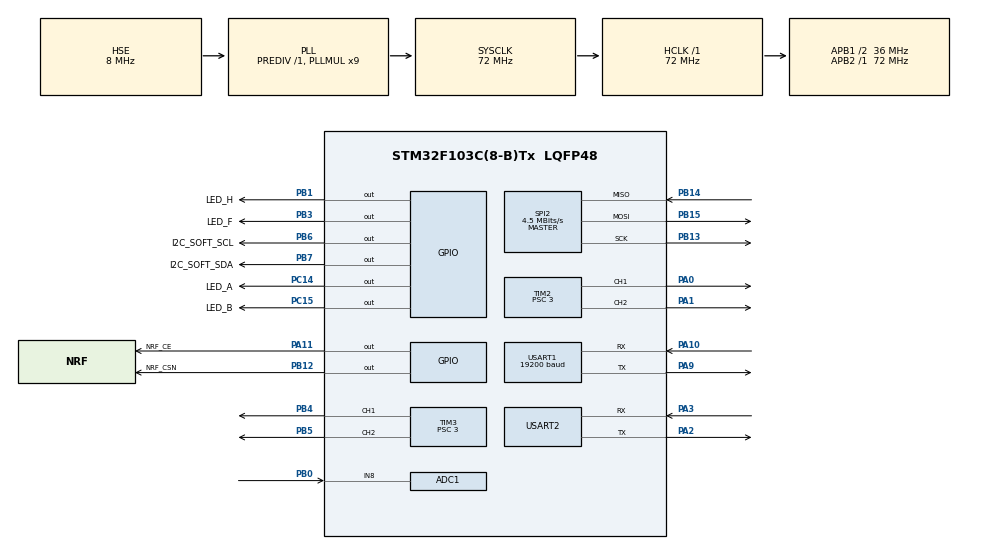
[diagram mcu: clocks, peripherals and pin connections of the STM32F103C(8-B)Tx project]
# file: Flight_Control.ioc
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ADC1.Channel-0\#ChannelRegularConversion=ADC_CHANNEL_8
ADC1.ContinuousConvMode=ENABLE
ADC1.NbrOfConversionFlag=1
ADC1.Rank-0\#ChannelRegularConversion=1
ADC1.SamplingTime-0\#ChannelRegularConversion=ADC_SAMPLETIME_55CYCLES_5
ADC1.master=1
Dma.ADC1.0.Direction=DMA_PERIPH_TO_MEMORY
Dma.ADC1.0.Instance=DMA1_Channel1
Dma.ADC1.0.MemDataAlignment=DMA_MDATAALIGN_HALFWORD
Dma.ADC1.0.MemInc=DMA_MINC_ENABLE
Dma.ADC1.0.Mode=DMA_CIRCULAR
Dma.ADC1.0.PeriphDataAlignment=DMA_PDATAALIGN_HALFWORD
Dma.ADC1.0.PeriphInc=DMA_PINC_DISABLE
Dma.ADC1.0.Priority=DMA_PRIORITY_LOW
Dma.Request0=ADC1
IWDG.Prescaler=IWDG_PRESCALER_64
IWDG.Reload=625
Mcu.Family=STM32F1
Mcu.Name=STM32F103C(8-B)Tx
Mcu.Package=LQFP48
NVIC.PriorityGroup=NVIC_PRIORITYGROUP_4
NVIC.USART1_IRQn=true\:5\:0\:true\:false\:true\:true\:true\:true
PA0-WKUP.Signal=S_TIM2_CH1_ETR
PA1.Signal=S_TIM2_CH2
PA10.Mode=Asynchronous
PA10.Signal=USART1_RX
PA11.GPIO_Label=NRF_CE
PA11.PinState=GPIO_PIN_SET
PA11.Signal=GPIO_Output
PA13.Mode=Serial_Wire
PA13.Signal=SYS_JTMS-SWDIO
PA14.Mode=Serial_Wire
PA14.Signal=SYS_JTCK-SWCLK
PA2.Mode=Asynchronous
PA2.Signal=USART2_TX
PA3.Mode=Asynchronous
PA3.Signal=USART2_RX
PA9.Mode=Asynchronous
PA9.Signal=USART1_TX
PB0.Signal=ADCx_IN8
PB1.GPIO_Label=LED_H
PB1.PinState=GPIO_PIN_SET
PB1.Signal=GPIO_Output
PB12.GPIO_Label=NRF_CSN
PB12.PinState=GPIO_PIN_SET
PB12.Signal=GPIO_Output
PB13.Mode=Full_Duplex_Master
PB13.Signal=SPI2_SCK
PB14.Mode=Full_Duplex_Master
PB14.Signal=SPI2_MISO
PB15.Mode=Full_Duplex_Master
PB15.Signal=SPI2_MOSI
PB3.GPIO_Label=LED_F
PB3.PinState=GPIO_PIN_SET
PB3.Signal=GPIO_Output
PB4.Signal=S_TIM3_CH1
PB5.Signal=S_TIM3_CH2
PB6.GPIO_Label=I2C_SOFT_SCL
PB6.GPIO_ModeDefaultOutputPP=GPIO_MODE_OUTPUT_OD
PB6.GPIO_PuPd=GPIO_NOPULL
PB6.PinState=GPIO_PIN_SET
PB6.Signal=GPIO_Output
PB7.GPIO_Label=I2C_SOFT_SDA
PB7.GPIO_ModeDefaultOutputPP=GPIO_MODE_OUTPUT_OD
PB7.GPIO_PuPd=GPIO_NOPULL
PB7.PinState=GPIO_PIN_SET
PB7.Signal=GPIO_Output
PC14-OSC32_IN.GPIO_Label=LED_A
PC14-OSC32_IN.PinState=GPIO_PIN_SET
PC14-OSC32_IN.Signal=GPIO_Output
PC15-OSC32_OUT.GPIO_Label=LED_B
PC15-OSC32_OUT.PinState=GPIO_PIN_SET
PC15-OSC32_OUT.Signal=GPIO_Output
PD0-OSC_IN.Mode=HSE-External-Oscillator
PD0-OSC_IN.Signal=RCC_OSC_IN
PD1-OSC_OUT.Mode=HSE-External-Oscillator
PD1-OSC_OUT.Signal=RCC_OSC_OUT
ProjectManager.HeapSize=0x200
ProjectManager.StackSize=0x400
ProjectManager.TargetToolchain=CMake
RCC.ADCPresc=RCC_ADCPCLK2_DIV6
RCC.AHBFreq_Value=72000000
RCC.APB1CLKDivider=RCC_HCLK_DIV2
RCC.APB1Freq_Value=36000000
RCC.APB1TimFreq_Value=72000000
RCC.APB2Freq_Value=72000000
RCC.APB2TimFreq_Value=72000000
RCC.HCLKFreq_Value=72000000
RCC.PLLMUL=RCC_PLL_MUL9
RCC.PLLSourceVirtual=RCC_PLLSOURCE_HSE
RCC.SYSCLKFreq_VALUE=72000000
RCC.SYSCLKSource=RCC_SYSCLKSOURCE_PLLCLK
RCC.USBFreq_Value=72000000
SH.ADCx_IN8.0=ADC1_IN8,IN8
SH.S_TIM2_CH1_ETR.0=TIM2_CH1,PWM Generation1 CH1
SH.S_TIM2_CH2.0=TIM2_CH2,PWM Generation2 CH2
SH.S_TIM3_CH1.0=TIM3_CH1,PWM Generation1 CH1
SH.S_TIM3_CH2.0=TIM3_CH2,PWM Generation2 CH2
SPI2.BaudRatePrescaler=SPI_BAUDRATEPRESCALER_8
SPI2.CalculateBaudRate=4.5 MBits/s
SPI2.Direction=SPI_DIRECTION_2LINES
SPI2.Mode=SPI_MODE_MASTER
SPI2.VirtualType=VM_MASTER
TIM2.AutoReloadPreload=TIM_AUTORELOAD_PRELOAD_ENABLE
TIM2.Channel-PWM\ Generation1\ CH1=TIM_CHANNEL_1
TIM2.Channel-PWM\ Generation2\ CH2=TIM_CHANNEL_2
TIM2.Period=999
TIM2.Prescaler=3
TIM3.AutoReloadPreload=TIM_AUTORELOAD_PRELOAD_ENABLE
TIM3.Channel-PWM\ Generation1\ CH1=TIM_CHANNEL_1
TIM3.Channel-PWM\ Generation2\ CH2=TIM_CHANNEL_2
TIM3.Period=999
TIM3.Prescaler=3
USART1.BaudRate=19200
USART1.VirtualMode=VM_ASYNC
USART2.VirtualMode=VM_ASYNC
VP_IWDG_VS_IWDG.Mode=IWDG_Activate
board=custom

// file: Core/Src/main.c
/* USER CODE BEGIN Header */
/**
  ******************************************************************************
  * @file           : main.c
  * @brief          : Main program body
  ******************************************************************************
  * @attention
  *
  * Copyright (c) 2026 STMicroelectronics.
  * All rights reserved.
  *
  * This software is licensed under terms that can be found in the LICENSE file
  * in the root directory of this software component.
  * If no LICENSE file comes with this software, it is provided AS-IS.
  *
  ******************************************************************************
  */
/* USER CODE END Header */
#include "main.h"
#include "adc.h"
#include "dma.h"
#include "iwdg.h"
#include "spi.h"
#include "tim.h"
#include "usart.h"
#include "gpio.h"

/* USER CODE BEGIN Includes */
#include "app.h"
#include "scheduler.h"
#include "led_ctrl.h"
/* USER CODE END Includes */

void SystemClock_Config(void);

int main(void)
{

  /* MCU Configuration--------------------------------------------------------*/

  /* Reset of all peripherals, Initializes the Flash interface and the Systick. */
  HAL_Init();

  /* Configure the system clock */
  SystemClock_Config();

  /* Initialize all configured peripherals */
  MX_GPIO_Init();
  MX_DMA_Init();
  MX_ADC1_Init();
  MX_IWDG_Init();
  MX_SPI2_Init();
  MX_TIM2_Init();
  MX_TIM3_Init();
  MX_USART1_UART_Init();
  MX_USART2_UART_Init();
  /* USER CODE BEGIN 2 */
  if (!App_Init())
  {
      LED_Ctrl_Error_Loop();
  }
  /* USER CODE END 2 */

  /* Infinite loop */
  /* USER CODE BEGIN WHILE */
  while (1)
  {
    Scheduler_Run();
    /* USER CODE END WHILE */

  }
}

void SystemClock_Config(void)
{
  RCC_OscInitTypeDef RCC_OscInitStruct = {0};
  RCC_ClkInitTypeDef RCC_ClkInitStruct = {0};
  RCC_PeriphCLKInitTypeDef PeriphClkInit = {0};

  /** Initializes the RCC Oscillators according to the specified parameters
  * in the RCC_OscInitTypeDef structure.
  */
  RCC_OscInitStruct.OscillatorType = RCC_OSCILLATORTYPE_LSI|RCC_OSCILLATORTYPE_HSE;
  RCC_OscInitStruct.HSEState = RCC_HSE_ON;
  RCC_OscInitStruct.HSEPredivValue = RCC_HSE_PREDIV_DIV1;
  RCC_OscInitStruct.HSIState = RCC_HSI_ON;
  RCC_OscInitStruct.LSIState = RCC_LSI_ON;
  RCC_OscInitStruct.PLL.PLLState = RCC_PLL_ON;
  RCC_OscInitStruct.PLL.PLLSource = RCC_PLLSOURCE_HSE;
  RCC_OscInitStruct.PLL.PLLMUL = RCC_PLL_MUL9;
  if (HAL_RCC_OscConfig(&RCC_OscInitStruct) != HAL_OK)
  {
    Error_Handler();
  }

  /** Initializes the CPU, AHB and APB buses clocks
  */
  RCC_ClkInitStruct.ClockType = RCC_CLOCKTYPE_HCLK|RCC_CLOCKTYPE_SYSCLK
                              |RCC_CLOCKTYPE_PCLK1|RCC_CLOCKTYPE_PCLK2;
  RCC_ClkInitStruct.SYSCLKSource = RCC_SYSCLKSOURCE_PLLCLK;
  RCC_ClkInitStruct.AHBCLKDivider = RCC_SYSCLK_DIV1;
  RCC_ClkInitStruct.APB1CLKDivider = RCC_HCLK_DIV2;
  RCC_ClkInitStruct.APB2CLKDivider = RCC_HCLK_DIV1;

  if (HAL_RCC_ClockConfig(&RCC_ClkInitStruct, FLASH_LATENCY_2) != HAL_OK)
  {
    Error_Handler();
  }
  PeriphClkInit.PeriphClockSelection = RCC_PERIPHCLK_ADC;
  PeriphClkInit.AdcClockSelection = RCC_ADCPCLK2_DIV6;
  if (HAL_RCCEx_PeriphCLKConfig(&PeriphClkInit) != HAL_OK)
  {
    Error_Handler();
  }
}

void Error_Handler(void)
{
  __disable_irq();
  while (1)
  {
  }
}
